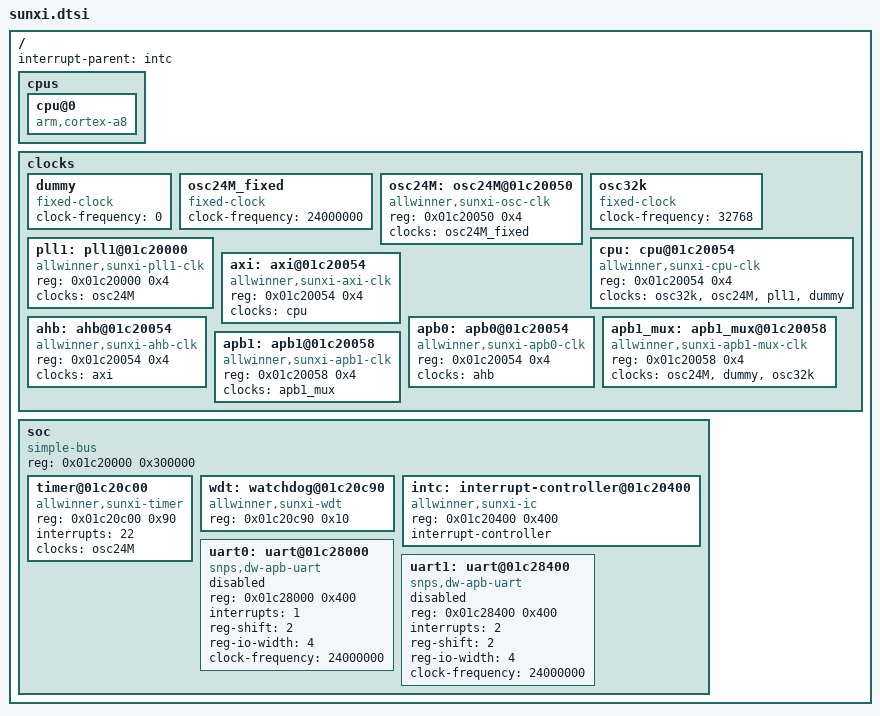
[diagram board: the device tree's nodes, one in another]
/*
 * Copyright 2012 Maxime Ripard
 *
 * Maxime Ripard <maxime.ripard@free-electrons.com>
 *
 * The code contained herein is licensed under the GNU General Public
 * License. You may obtain a copy of the GNU General Public License
 * Version 2 or later at the following locations:
 *
 * http://www.opensource.org/licenses/gpl-license.html
 * http://www.gnu.org/copyleft/gpl.html
 */

/include/ "skeleton.dtsi"

/ {
	interrupt-parent = <&intc>;

	cpus {
		cpu@0 {
			compatible = "arm,cortex-a8";
		};
	};

	clocks {
		#address-cells = <1>;
		#size-cells = <1>;
		ranges;

		/*
		 * This is a dummy clock, to be used as placeholder on
		 * other mux clocks when a specific parent clock is not
		 * yet implemented. It should be dropped when the driver
		 * is complete.
		 */
		dummy: dummy {
			#clock-cells = <0>;
			compatible = "fixed-clock";
			clock-frequency = <0>;
		};

		osc24M_fixed: osc24M_fixed {
			#clock-cells = <0>;
			compatible = "fixed-clock";
			clock-frequency = <24000000>;
		};

		osc24M: osc24M@01c20050 {
			#clock-cells = <0>;
			compatible = "allwinner,sunxi-osc-clk";
			reg = <0x01c20050 0x4>;
			clocks = <&osc24M_fixed>;
		};

		osc32k: osc32k {
			#clock-cells = <0>;
			compatible = "fixed-clock";
			clock-frequency = <32768>;
		};

		pll1: pll1@01c20000 {
			#clock-cells = <0>;
			compatible = "allwinner,sunxi-pll1-clk";
			reg = <0x01c20000 0x4>;
			clocks = <&osc24M>;
		};

		/* dummy is 200M */
		cpu: cpu@01c20054 {
			#clock-cells = <0>;
			compatible = "allwinner,sunxi-cpu-clk";
			reg = <0x01c20054 0x4>;
			clocks = <&osc32k>, <&osc24M>, <&pll1>, <&dummy>;
		};

		axi: axi@01c20054 {
			#clock-cells = <0>;
			compatible = "allwinner,sunxi-axi-clk";
			reg = <0x01c20054 0x4>;
			clocks = <&cpu>;
		};

		ahb: ahb@01c20054 {
			#clock-cells = <0>;
			compatible = "allwinner,sunxi-ahb-clk";
			reg = <0x01c20054 0x4>;
			clocks = <&axi>;
		};

		apb0: apb0@01c20054 {
			#clock-cells = <0>;
			compatible = "allwinner,sunxi-apb0-clk";
			reg = <0x01c20054 0x4>;
			clocks = <&ahb>;
		};

		/* dummy is pll62 */
		apb1_mux: apb1_mux@01c20058 {
			#clock-cells = <0>;
			compatible = "allwinner,sunxi-apb1-mux-clk";
			reg = <0x01c20058 0x4>;
			clocks = <&osc24M>, <&dummy>, <&osc32k>;
		};

		apb1: apb1@01c20058 {
			#clock-cells = <0>;
			compatible = "allwinner,sunxi-apb1-clk";
			reg = <0x01c20058 0x4>;
			clocks = <&apb1_mux>;
		};
	};

	soc {
		compatible = "simple-bus";
		#address-cells = <1>;
		#size-cells = <1>;
		reg = <0x01c20000 0x300000>;
		ranges;

		timer@01c20c00 {
			compatible = "allwinner,sunxi-timer";
			reg = <0x01c20c00 0x90>;
			interrupts = <22>;
			clocks = <&osc24M>;
		};

		wdt: watchdog@01c20c90 {
			compatible = "allwinner,sunxi-wdt";
			reg = <0x01c20c90 0x10>;
		};

		intc: interrupt-controller@01c20400 {
			compatible = "allwinner,sunxi-ic";
			reg = <0x01c20400 0x400>;
			interrupt-controller;
			#interrupt-cells = <1>;
		};

		uart0: uart@01c28000 {
			compatible = "snps,dw-apb-uart";
			reg = <0x01c28000 0x400>;
			interrupts = <1>;
			reg-shift = <2>;
			reg-io-width = <4>;
			clock-frequency = <24000000>;
			status = "disabled";
		};

		uart1: uart@01c28400 {
			compatible = "snps,dw-apb-uart";
			reg = <0x01c28400 0x400>;
			interrupts = <2>;
			reg-shift = <2>;
			reg-io-width = <4>;
			clock-frequency = <24000000>;
			status = "disabled";
		};
	};
};
